# NUC123AN_v1 register map
File version: 1.0
Registers are 32-bit, read-write, reset 0x0 unless marked. A register's access mark holds for its fields unless they carry their own. Offsets are from the block's base; [hi:lo] are bit positions; 'fields as' and 'values as' point back to an identical list.

## TMR23 — TIMER Register Map
Base 0x40110000
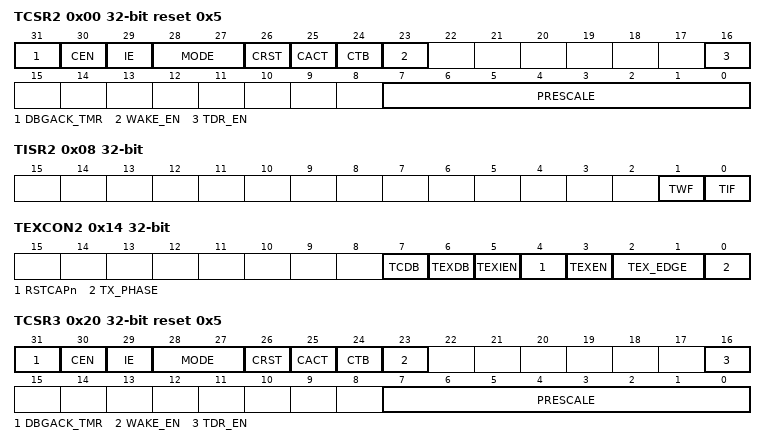
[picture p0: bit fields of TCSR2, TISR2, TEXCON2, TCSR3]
0x00 TCSR2 reset 0x5 — Timer2 Control and Status Register
  [31] DBGACK_TMR — ICE debug mode acknowledge Disable (Write-protection Bit). TIMER counter will keep going no matter ICE debug mode acknowledged or not.
    0=ICE debug mode acknowledgement effects TIMER counting; 1=ICE debug mode acknowledgement disabled
  [30] CEN — Timer Enable Bit
    0=Stops/Suspends counting; 1=Starts counting
  [29] IE — Interrupt Enable Bit. If timer interrupt is enabled, the timer asserts its interrupt signal when the associated up-timer value is equal to TCMPR.
    0=Timer Interrupt Disabled; 1=Timer Interrupt Enabled
  [28:27] MODE — Timer Operating Mode
  [26] CRST — Timer Reset Bit. Set this bit will reset the 24-bit up-timer, 8-bit pre-scale counter and also force CEN to 0.
    0=No effect; 1=Reset Timer's 8-bit pre-scale counter, internal 24-bit up-timer and CEN bit
  [25] CACT ro — Timer Active Status Bit (Read only). This bit indicates the up-timer status.
    0=Timer is not active; 1=Timer is active
  [24] CTB — Counter Mode Enable Bit. This bit is the counter mode enable bit. When Timer is used as an event counter, this bit should be set to 1 and Timer will work as an event counter. The counter detect phase can be selected as rising/falling edge of external pin by TX_PHASE field.
    0=Counter mode Disabled; 1=Counter mode Enabled
  [23] WAKE_EN — Wake-up Enable. When WAKE_EN is set and the TIF is set, the timer controller will generator a wake-up trigger event to CPU.
    0=Wake-up trigger event Disabled; 1=Wake-up trigger event Enabled
  [16] TDR_EN — Data Load Enable. When TDR_EN is set, TDR (Timer Data Register) will be updated continuously with the 24-bit up-timer value as the timer is counting.
    0=Timer Data Register update Disabled; 1=Timer Data Register update Enabled
  [7:0] PRESCALE — Pre-scale Counter
0x04 TCMPR2 — Timer2 Compare Register
  [23:0] TCMP — Timer Compared Value. Note1: Never write 0x0 or 0x1 in TCMP, or the core will run into unknown state. Note2: When timer is operating in continuous counting mode, the 24-bit up-timer will count continuously if software writes a new value into TCMP. If timer is operating at other modes, the 24-bit up-timer will restart counting and using newest TCMP value to be the compared value if software writes a new value into TCMP.
0x08 TISR2 — Timer2 Interrupt Status Register
  [1] TWF — Timer Wakeup Flag. If timer causes CPU wakes up from power-down mode, this bit will be set to high. It must be cleared by software with a write 1 to this bit.
    0=Timer does not cause CPU wakeup; 1=CPU wakes up from sleep or power-down mode by timer time-out
  [0] TIF — Timer Interrupt Flag. This bit indicates the interrupt status of timer. TIF bit is set by hardware when the up counting value of internal 24-bit up-timer matches the timer compared value (TCMP). It is cleared by writing 1 to this bit.
0x0C TDR2 ro — Timer2 Data Register
  [23:0] TDR — Timer Data Register. User can read TDR for getting current 24- bits up event counter value if TCSR[24] is 1
0x10 TCAP2 ro — Timer2 Capture Data Register
  [23:0] TCAP — Timer Capture Data Register. When TEXEN (TEXCON[3]) is set, RSTCAPn(TTXCON[4]) is 0, and the transition on the TEX pins associated TEX_EDGE(TEXCON[2:1]) setting is occurred, the internal 24-bit up-timer value will be loaded into TCAP. User can read this register for the counter value.
0x14 TEXCON2 — Timer2 External Control Register
  [7] TCDB — Timer Counter Pin De-bounce Enable Bit. If this bit is enabled, the edge of TM0~TM3 pin is detected with de-bounce circuit.
    0=De-bounce Disabled; 1=De-bounce Enabled
  [6] TEXDB — Timer External Capture Pin De-bounce Enable Bit. If this bit is enabled, the edge of T0EX~T3EX pin is detected with de-bounce circuit.
    0=De-bounce Disabled; 1=De-bounce Enabled
  [5] TEXIEN — Timer External Interrupt Enable Bit
    0=Timer external interrupt Disabled; 1=Timer external interrupt Enabled
  [4] RSTCAPn — Timer External Reset Counter/Capture Mode Selection
    0=TEX transition is used as the timer capture function; 1=TEX transition is used as the timer counter reset function
  [3] TEXEN — Timer External Pin Enable. This bit enables the reset/capture function on the TEX pin.
    0=TEX pin will be ignored; 1=Transition detected on the TEX pin will result in capture or reset of timer counter
  [2:1] TEX_EDGE — Timer External Pin Edge Detect
    0=1 to 0 transition on TEX will be detected; 1=0 to 1 transition on TEX will be detected; 2=Either 1 to 0 or 0 to 1 transition on TEX will be detected
  [0] TX_PHASE — Timer External Count Phase. This bit indicates the external count pin phase.
    0=A falling edge of external count pin will be counted; 1=A rising edge of external count pin will be counted
0x18 TEXISR2 — Timer2 External Interrupt Status Register
  [0] TEXIF — Timer External Interrupt Flag. This bit indicates the external interrupt status of Timer. This bit is set by hardware when TEXEN (TEXCON[3]) is to 1, and the transition on the TEX pins associated with TEX_EDGE (TEXCON[2:1]) setting is occurred. It is cleared by writing 1 to this bit.
0x20 TCSR3 reset 0x5 — Timer3 Control and Status Register
  fields as TCSR2
0x24 TCMPR3 — Timer3 Compare Register
  fields as TCMPR2
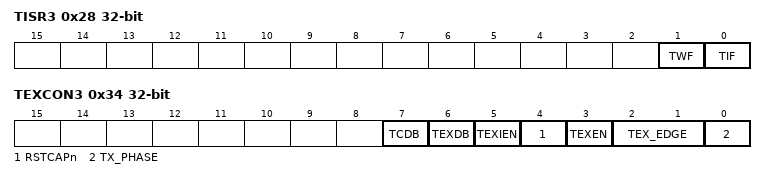
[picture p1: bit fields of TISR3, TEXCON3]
0x28 TISR3 — Timer3 Interrupt Status Register
  fields as TISR2
0x2C TDR3 ro — Timer3 Data Register
  fields as TDR2
0x30 TCAP3 ro — Timer3 Capture Data Register
  fields as TCAP2
0x34 TEXCON3 — Timer3 External Control Register
  fields as TEXCON2
0x38 TEXISR3 — Timer3 External Interrupt Status Register
  fields as TEXISR2
